# MCASP0_CFG register map
Vendor: Texas Instruments
Registers are 32-bit, read-write, reset 0x0 unless marked. A register's access mark holds for its fields unless they carry their own. Offsets are as the file gives them; [hi:lo] are bit positions.

## MCASP0_CFG (part 3 of 3)
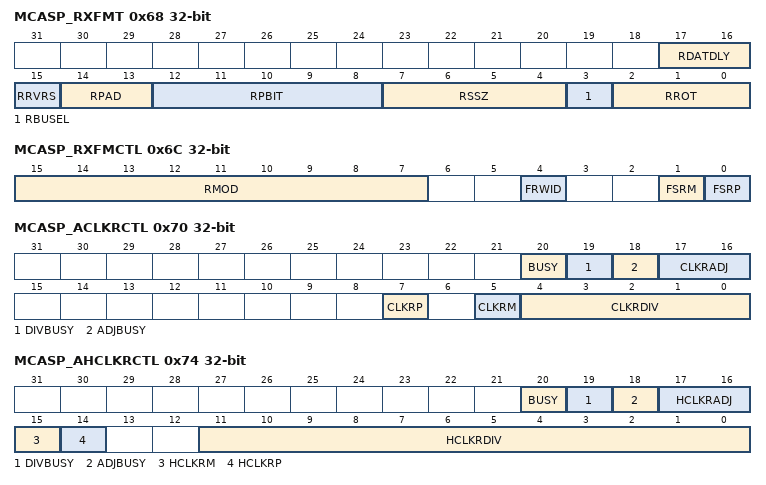
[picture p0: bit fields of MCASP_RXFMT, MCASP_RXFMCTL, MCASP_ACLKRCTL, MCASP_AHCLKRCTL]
0x68 MCASP_RXFMT
  [17:16] RDATDLY — Receive bit delay.0h = 0-bit delay. The first receive data bit, AXRn, occurs in same ACLKR cycle as the receive frame sync (AFSR). 1h = 1-bit delay. The first receive data bit, AXRn, occurs one ACLKR cycle after the receive frame sync (AFSR). 2h = 2-bit delay. The first receive data bit, AXRn, occurs two ACLKR cycles after the receive frame sync (AFSR). 3h = Reserved.
  [15] RRVRS — Receive serial bitstream order.0h = Bitstream is LSB first. No bit reversal is performed in receive format bit reverse unit. 1h = Bitstream is MSB first. Bit reversal is performed in receive format bit reverse unit.
  [14:13] RPAD — Pad value for extra bits in slot not belonging to the word. This field only applies to bits when MCASP_RMASK[n] = 0. 0h = Pad extra bits with 0. 1h = Pad extra bits with 1. 2h = Pad extra bits with one of the bits from the word as specified by RPBIT bits. 3h = Reserved.
  [12:8] RPBIT — RPBIT value determines which bit [as read by the CPU or DMA from RBUF[n]] is used to pad the extra bits. This field only applies when RPAD = 2h. 0h = Pad with bit 0 value. 1h = Pad with bit 1 to bit 31 value from 1h to 1Fh.
  [7:4] RSSZ — Receive slot size.0h = Reseved. 1h = Reserved. 2h = Reserved. 3h = Slot size is 8 bits. 4h = Reserved 5h = Slot size is 12 bits. 6h = Reserved 7h = Slot size is 16 bits. 8h = Reserved 9h = Slot size is 20 bits. Ah = Reserved Bh = Slot size is 24 bits Ch = Reserved Dh = Slot size is 28 bits. Eh = Reserved Fh = Slot size is 32 bits.
  [3] RBUSEL — Selects whether reads from serializer buffer XRBUF[n] originate from the configuration bus [CFG] or the data [DAT] port.0h = Reads from XRBUF[n] originate on data port. Reads from XRBUF[n] on configuration bus are ignored. 1h = Reads from XRBUF[n] originate on configuration bus. Reads from XRBUF[n] on data port are ignored.
  [2:0] RROT — Right-rotation value for receive rotate right format unit.0h = Rotate right by 0 (no rotation). 1h = Rotate right by 4 bit positions. 2h = Rotate right by 8 bit positions. 3h = Rotate right by 12 bit positions. 4h = Rotate right by 16 bit positions. 5h = Rotate right by 20 bit positions. 6h = Rotate right by 24 bit positions. 7h = Rotate right by 28 bit positions.
0x6C MCASP_RXFMCTL
  [15:7] RMOD — Receive frame sync mode select bits. 1FFh = Reserved from 181h to 1FFh. 0h = Burst mode. 1h = Reserved. 2h = 2-slot TDM (I2S mode) to 32-slot TDM from 2h to 20h. 21h = Reserved from 21h to 17Fh. 180h = 384-slot TDM (external DIR IC inputting 384-slot DIR frames to McASP over I2S interface). 181h = Reserved from 181h to 1FFh.
  [4] FRWID — Receive frame sync width select bit indicates the width of the receive frame sync [AFSR] during its active period.0h = Single bit. 1h = Single word.
  [1] FSRM — Receive frame sync generation select bit.0h = Externally-generated receive frame sync. 1h = Internally-generated receive frame sync.
  [0] FSRP — Receive frame sync polarity select bit.0h = A rising edge on receive frame sync (AFSR) indicates the beginning of a frame. 1h = A falling edge on receive frame sync (AFSR) indicates the beginning of a frame.
0x70 MCASP_ACLKRCTL access per field
  [20] BUSY rw — Тhe OR of bits 18 and 19, indicating that some clk change is in progress when high.
  [19] DIVBUSY rw — Divider change in progress (same behavior as bit 18)
  [18] ADJBUSY rw — One-shot adj in progress (a BUSY bit that is set when an adj is in progress, cleared when the adjustment has taken effect)
  [17:16] CLKRADJ wo — CLKRDIV one-shot adjustment contro.l If CLKRDIV is set such that there are “m” input clocks per one output clock, then for one output cycle: 0h = (m+0) input clocks per output clock, no adjustment 1h = (m-1) input clocks per output clock 2h = (m+1) input clocks per output clock 3h = (m+0) input clocks per output clock, no adjustment
  [7] CLKRP rw — Bitstream clock polarity for receive section: 0h = Falling Edge. Receiver captures sample data on the falling edge of the serial clock, so the EXTERNAL transmitter driving this receiver must shift data out on the rising edge of the serial clock. 1h = Rising Edge. Receiver captures sample data on the rising edge of the serial clock, so the EXTERNAL transmitter driving this receiver must shift data out on the falling edge of the serial clock.
  [5] CLKRM rw — Receive clock source: 0h = External Transmit Clock From ACLKR pin 1h = Internal (output of divider), output clock on ACLKR pin.
  [4:0] CLKRDIV rw — Receive clock divide ratio from high frequency transmit clock: 00000b = /1 00001b = /2 . . . 11111b = /32 All values between /1 and /32 are supported.
0x74 MCASP_AHCLKRCTL access per field
  [20] BUSY rw — The OR of bits 18 and 19, indicating that some clk change is in progress when high.
  [19] DIVBUSY rw — Divider change in progress (same behavior as bit 18)
  [18] ADJBUSY rw — One-shot adj in progress (a BUSY bit that is set when an adj is in progress, cleared when the adjustment has taken effect).
  [17:16] HCLKRADJ wo — HCLKRDIV one-shot adjustment control If HCLKRDIV is set such that there are “m” input clocks per one output clock, then for one output cycle: 0h = (m+0) input clocks per output clock 1h = (m-1) input clocks per output clock 2h = (m+1) input clocks per output clock 3h = (m+0) input clocks per output clock
  [15] HCLKRM rw — High frequency receive clock source: 0h = External Clock on AHCLKR pin passes through divider (typically set to /1). 1h = Internal, CPU Clock passed through divider. Divider output on AHCLKR pin.
  [14] HCLKRP rw — high frequency clock polarity: 0h = AHCLKR not inverted before divider. Rising Edge of AHCLKR causes edges on ACLKR when internally generated. 1h = AHCLKR inverted before divider. Falling Edge of AHCLK causes edges on ACLKR when internally generated. For the /1 clock divider case, AHCLKR is just passed through to ACLKR. For odd dividers, both edges of AHCLKR cause ACLKR to toggle but this polarity bit defines which is first edge of AHCLKR to affect ACLKR.
  [11:0] HCLKRDIV rw — Receive clock divide ratio from CPU master clock or external high frequency clock: 0000 0000 0000b = /1 0000 0000 0001b = /2 . . . 1111 1111 1111b = /4096 All values between /1, and /4096 are supported.
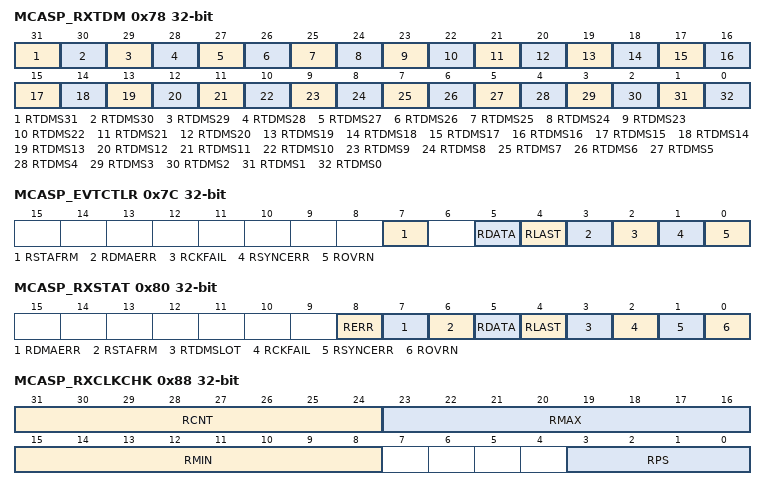
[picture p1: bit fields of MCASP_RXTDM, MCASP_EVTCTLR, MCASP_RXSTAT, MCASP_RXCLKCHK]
0x78 MCASP_RXTDM
  [31] RTDMS31 — Receiver mode during TDM time slot 31.0h = Receive TDM time slot 31 is inactive. The receive serializer does not shift in data during this slot. 1h = Receive TDM time slot 31 is active. The receive serializer shifts in data during this slot.
  [30] RTDMS30 — Receiver mode during TDM time slot 30.0h = Receive TDM time slot 30 is inactive. The receive serializer does not shift in data during this slot. 1h = Receive TDM time slot 30 is active. The receive serializer shifts in data during this slot.
  [29] RTDMS29 — Receiver mode during TDM time slot 29.0h = Receive TDM time slot 29 is inactive. The receive serializer does not shift in data during this slot. 1h = Receive TDM time slot 29 is active. The receive serializer shifts in data during this slot.
  [28] RTDMS28 — Receiver mode during TDM time slot 28.0h = Receive TDM time slot 28 is inactive. The receive serializer does not shift in data during this slot. 1h = Receive TDM time slot 28 is active. The receive serializer shifts in data during this slot.
  [27] RTDMS27 — Receiver mode during TDM time slot 27.0h = Receive TDM time slot 27 is inactive. The receive serializer does not shift in data during this slot. 1h = Receive TDM time slot 27 is active. The receive serializer shifts in data during this slot.
  [26] RTDMS26 — Receiver mode during TDM time slot 26.0h = Receive TDM time slot 26 is inactive. The receive serializer does not shift in data during this slot. 1h = Receive TDM time slot 26 is active. The receive serializer shifts in data during this slot.
  [25] RTDMS25 — Receiver mode during TDM time slot 25.0h = Receive TDM time slot 25 is inactive. The receive serializer does not shift in data during this slot. 1h = Receive TDM time slot 25 is active. The receive serializer shifts in data during this slot.
  [24] RTDMS24 — Receiver mode during TDM time slot 24.0h = Receive TDM time slot 24 is inactive. The receive serializer does not shift in data during this slot. 1h = Receive TDM time slot 24 is active. The receive serializer shifts in data during this slot.
  [23] RTDMS23 — Receiver mode during TDM time slot 23.0h = Receive TDM time slot 23 is inactive. The receive serializer does not shift in data during this slot. 1h = Receive TDM time slot 23 is active. The receive serializer shifts in data during this slot.
  [22] RTDMS22 — Receiver mode during TDM time slot 22.0h = Receive TDM time slot 22 is inactive. The receive serializer does not shift in data during this slot. 1h = Receive TDM time slot 22 is active. The receive serializer shifts in data during this slot.
  [21] RTDMS21 — Receiver mode during TDM time slot 21.0h = Receive TDM time slot 21 is inactive. The receive serializer does not shift in data during this slot. 1h = Receive TDM time slot 21 is active. The receive serializer shifts in data during this slot.
  [20] RTDMS20 — Receiver mode during TDM time slot 20.0h = Receive TDM time slot 20 is inactive. The receive serializer does not shift in data during this slot. 1h = Receive TDM time slot 20 is active. The receive serializer shifts in data during this slot.
  [19] RTDMS19 — Receiver mode during TDM time slot 19.0h = Receive TDM time slot 19 is inactive. The receive serializer does not shift in data during this slot. 1h = Receive TDM time slot 19 is active. The receive serializer shifts in data during this slot.
  [18] RTDMS18 — Receiver mode during TDM time slot 18.0h = Receive TDM time slot 18 is inactive. The receive serializer does not shift in data during this slot. 1h = Receive TDM time slot 18 is active. The receive serializer shifts in data during this slot.
  [17] RTDMS17 — Receiver mode during TDM time slot 17.0h = Receive TDM time slot 17 is inactive. The receive serializer does not shift in data during this slot. 1h = Receive TDM time slot 17 is active. The receive serializer shifts in data during this slot.
  [16] RTDMS16 — Receiver mode during TDM time slot 16.0h = Receive TDM time slot 16 is inactive. The receive serializer does not shift in data during this slot. 1h = Receive TDM time slot 16 is active. The receive serializer shifts in data during this slot.
  [15] RTDMS15 — Receiver mode during TDM time slot 15.0h = Receive TDM time slot 15 is inactive. The receive serializer does not shift in data during this slot. 1h = Receive TDM time slot 15 is active. The receive serializer shifts in data during this slot.
  [14] RTDMS14 — Receiver mode during TDM time slot 14.0h = Receive TDM time slot 14 is inactive. The receive serializer does not shift in data during this slot. 1h = Receive TDM time slot 14 is active. The receive serializer shifts in data during this slot.
  [13] RTDMS13 — Receiver mode during TDM time slot 13.0h = Receive TDM time slot 13 is inactive. The receive serializer does not shift in data during this slot. 1h = Receive TDM time slot 13 is active. The receive serializer shifts in data during this slot.
  [12] RTDMS12 — Receiver mode during TDM time slot 12.0h = Receive TDM time slot 12 is inactive. The receive serializer does not shift in data during this slot. 1h = Receive TDM time slot 12 is active. The receive serializer shifts in data during this slot.
  [11] RTDMS11 — Receiver mode during TDM time slot 11.0h = Receive TDM time slot 11 is inactive. The receive serializer does not shift in data during this slot. 1h = Receive TDM time slot 11 is active. The receive serializer shifts in data during this slot.
  [10] RTDMS10 — Receiver mode during TDM time slot 10.0h = Receive TDM time slot 10 is inactive. The receive serializer does not shift in data during this slot. 1h = Receive TDM time slot 10 is active. The receive serializer shifts in data during this slot.
  [9] RTDMS9 — Receiver mode during TDM time slot 9.0h = Receive TDM time slot 9 is inactive. The receive serializer does not shift in data during this slot. 1h = Receive TDM time slot 9 is active. The receive serializer shifts in data during this slot.
  [8] RTDMS8 — Receiver mode during TDM time slot 8.0h = Receive TDM time slot 8 is inactive. The receive serializer does not shift in data during this slot. 1h = Receive TDM time slot 8 is active. The receive serializer shifts in data during this slot.
  [7] RTDMS7 — Receiver mode during TDM time slot 7.0h = Receive TDM time slot 7 is inactive. The receive serializer does not shift in data during this slot. 1h = Receive TDM time slot 7 is active. The receive serializer shifts in data during this slot.
  [6] RTDMS6 — Receiver mode during TDM time slot 6.0h = Receive TDM time slot 6 is inactive. The receive serializer does not shift in data during this slot. 1h = Receive TDM time slot 6 is active. The receive serializer shifts in data during this slot.
  [5] RTDMS5 — Receiver mode during TDM time slot 5.0h = Receive TDM time slot 5 is inactive. The receive serializer does not shift in data during this slot. 1h = Receive TDM time slot 5 is active. The receive serializer shifts in data during this slot.
  [4] RTDMS4 — Receiver mode during TDM time slot 4.0h = Receive TDM time slot 4 is inactive. The receive serializer does not shift in data during this slot. 1h = Receive TDM time slot 4 is active. The receive serializer shifts in data during this slot.
  [3] RTDMS3 — Receiver mode during TDM time slot 3.0h = Receive TDM time slot 3 is inactive. The receive serializer does not shift in data during this slot. 1h = Receive TDM time slot 3 is active. The receive serializer shifts in data during this slot.
  [2] RTDMS2 — Receiver mode during TDM time slot 2.0h = Receive TDM time slot 2 is inactive. The receive serializer does not shift in data during this slot. 1h = Receive TDM time slot 2 is active. The receive serializer shifts in data during this slot.
  [1] RTDMS1 — Receiver mode during TDM time slot 1.0h = Receive TDM time slot 1 is inactive. The receive serializer does not shift in data during this slot. 1h = Receive TDM time slot 1 is active. The receive serializer shifts in data during this slot.
  [0] RTDMS0 — Receiver mode during TDM time slot 0.0h = Receive TDM time slot 0 is inactive. The receive serializer does not shift in data during this slot. 1h = Receive TDM time slot 0 is active. The receive serializer shifts in data during this slot.
0x7C MCASP_EVTCTLR
  [7] RSTAFRM — Receive start of frame interrupt enable bit.0h = Interrupt is disabled. A receive start of frame interrupt does not generate a MCASP receive interrupt (RINT). 1h = Interrupt is enabled. A receive start of frame interrupt generates a MCASP receive interrupt (RINT).
  [5] RDATA — Receive data ready interrupt enable bit.0h = Interrupt is disabled. A receive data ready interrupt does not generate a MCASP receive interrupt (RINT). 1h = Interrupt is enabled. A receive data ready interrupt generates a MCASP receive interrupt (RINT).
  [4] RLAST — Receive last slot interrupt enable bit.0h = Interrupt is disabled. A receive last slot interrupt does not generate a MCASP receive interrupt (RINT). 1h = Interrupt is enabled. A receive last slot interrupt generates a MCASP receive interrupt (RINT).
  [3] RDMAERR — Receive DMA error interrupt enable bit.0h = Interrupt is disabled. A receive DMA error interrupt does not generate a MCASP receive interrupt (RINT). 1h = Interrupt is enabled. A receive DMA error interrupt generates a MCASP receive interrupt (RINT).
  [2] RCKFAIL — Receive clock failure interrupt enable bit.0h = Interrupt is disabled. A receive clock failure interrupt does not generate a MCASP receive interrupt (RINT). 1h = Interrupt is enabled. A receive clock failure interrupt generates a MCASP receive interrupt (RINT).
  [1] RSYNCERR — Unexpected receive frame sync interrupt enable bit.0h = Interrupt is disabled. An unexpected receive frame sync interrupt does not generate a MCASP receive interrupt (RINT). 1h = Interrupt is enabled. An unexpected receive frame sync interrupt generates a MCASP receive interrupt (RINT).
  [0] ROVRN — Receiver overrun interrupt enable bit.0h = Interrupt is disabled. A receiver overrun interrupt does not generate a MCASP receive interrupt (RINT). 1h = Interrupt is enabled. A receiver overrun interrupt generates a MCASP receive interrupt (RINT).
0x80 MCASP_RXSTAT
  [8] RERR — RERR bit always returns a logic-OR of: ROVRN OR RSYNCERR OR RCKFAIL OR RDMAERR. Allows a single bit to be checked to determine if a receiver error interrupt has occurred. 0h = No errors have occurred. 1h = An error has occurred.
  [7] RDMAERR — Receive DMA error flag. RDMAERR is set when the CPU or DMA reads more serializers through the data port in a given time slot than were programmed as receivers. Causes a receive interrupt [RINT], if this bit is set and RDMAERR in MCASP_RINTCTL is set. This bit is cleared by writing a 1 to this bit. Writing a 0 to this bit has no effect. 0h = Receive DMA error did not occur. 1h = Receive DMA error did occur.
  [6] RSTAFRM — Receive start of frame flag. Causes a receive interrupt [RINT], if this bit is set and RSTAFRM in MCASP_RINTCTL is set. This bit is cleared by writing a 1 to this bit. Writing a 0 to this bit has no effect. 0h = No new receive frame sync (AFSR) is detected. 1h = A new receive frame sync (AFSR) is detected.
  [5] RDATA — Receive data ready flag. Causes a receive interrupt [RINT], if this bit is set and RDATA in MCASP_RINTCTL is set. This bit is cleared by writing a 1 to this bit. Writing a 0 to this bit has no effect. 0h = No new data in RBUF. 1h = Data is transferred from XRSR to RBUF and ready to be serviced by the CPU or DMA. When RDATA is set, it always causes a DMA event (AREVT).
  [4] RLAST — Receive last slot flag. RLAST is set along with RDATA, if the current slot is the last slot in a frame. Causes a receive interrupt [RINT], if this bit is set and RLAST in MCASP_RINTCTL is set. This bit is cleared by writing a 1 to this bit. Writing a 0 to this bit has no effect. 0h = Current slot is not the last slot in a frame. 1h = Current slot is the last slot in a frame. RDATA is also set.
  [3] RTDMSLOT — Returns the LSB of MCASP_RSLOT. Allows a single read of MCASP_RSTAT to determine whether the current TDM time slot is even or odd. 0h = Current TDM time slot is odd. 1h = Current TDM time slot is even.
  [2] RCKFAIL — Receive clock failure flag. RCKFAIL is set when the receive clock failure detection circuit reports an error. Causes a receive interrupt [RINT], if this bit is set and RCKFAIL in MCASP_RINTCTL is set. This bit is cleared by writing a 1 to this bit. Writing a 0 to this bit has no effect. 0h = Receive clock failure did not occur. 1h = Receive clock failure did occur.
  [1] RSYNCERR — Unexpected receive frame sync flag. RSYNCERR is set when a new receive frame sync [AFSR] occurs before it is expected. Causes a receive interrupt [RINT], if this bit is set and RSYNCERR in MCASP_RINTCTL is set. This bit is cleared by writing a 1 to this bit. Writing a 0 to this bit has no effect. 0h = Unexpected receive frame sync did not occur. 1h = Unexpected receive frame sync did occur.
  [0] ROVRN — Receiver overrun flag. ROVRN is set when the receive serializer is instructed to transfer data from XRSR to RBUF, but the former data in RBUF has not yet been read by the CPU or DMA. Causes a receive interrupt [RINT], if this bit is set and ROVRN in MCASP_RINTCTL is set. This bit is cleared by writing a 1 to this bit. Writing a 0 to this bit has no effect. 0h = Receiver overrun did not occur. 1h = Receiver overrun did occur.
0x84 MCASP_RXTDMSLOT ro
  [9:0] RSLOTCNT — 0-17Fh = Current receive time slot count. Legal values: 0 to 383 [17Fh]. TDM function is not supported for &gt; 32 time slots. However, TDM time slot counter may count to 383 when used to receive a DIR block [transferred over TDM format].
0x88 MCASP_RXCLKCHK access per field
  [31:24] RCNT ro — Receive clock count value [from previous measurement]. The clock circuit continually counts the number of system clocks for every 32 receive high-frequency master clock [AHCLKR] signals, and stores the count in RCNT until the next measurement is taken.
  [23:16] RMAX rw — Receive clock maximum boundary. This 8 bit unsigned value sets the maximum allowed boundary for the clock check counter after 32 receive high-frequency master clock [AHCLKR] signals have been received. If the current counter value is greater than RMAX after counting 32 AHCLKR signals, RCKFAIL in MCASP_RSTAT is set. The comparison is performed using unsigned arithmetic.
  [15:8] RMIN rw — Receive clock minimum boundary. This 8 bit unsigned value sets the minimum allowed boundary for the clock check counter after 32 receive high-frequency master clock [AHCLKR] signals have been received. If RCNT is less than RMIN after counting 32 AHCLKR signals, RCKFAIL in MCASP_RSTAT is set. The comparison is performed using unsigned arithmetic.
  [3:0] RPS rw — Receive clock check prescaler value.0h = MCASP system clock divided by 1. 1h = MCASP system clock divided by 2. 2h = MCASP system clock divided by 4. 3h = MCASP system clock divided by 8. 4h = MCASP system clock divided by 16. 5h = MCASP system clock divided by 32. 6h = MCASP system clock divided by 64. 7h = MCASP system clock divided by 128. 8h = MCASP system clock divided by 256. 9h = Reserved from 9h to Fh.
0x8C MCASP_REVTCTL
  [0] RDATDMA — Receive data DMA request enable bit. If writing to this bit, always write the default value of 0. 0h = Receive data DMA request is enabled. 1h = Reserved
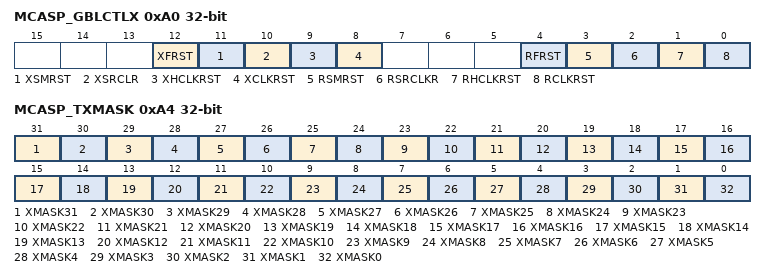
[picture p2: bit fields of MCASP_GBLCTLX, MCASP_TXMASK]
0xA0 MCASP_GBLCTLX access per field
  [12] XFRST rw — Transmit frame sync generator reset enable bit. A write to this bit affects the XFRST bit of MCASP_GBLCTL. 0h = Transmit frame sync generator is reset. 1h = Transmit frame sync generator is active.
  [11] XSMRST rw — Transmit state machine reset enable bit. A write to this bit affects the XSMRST bit of MCASP_GBLCTL. 0h = Transmit state machine is held in reset. 1h = Transmit state machine is released from reset.
  [10] XSRCLR rw — Transmit serializer clear enable bit. A write to this bit affects the XSRCLR bit of MCASP_GBLCTL. 0h = Transmit serializers are cleared. 1h = Transmit serializers are active.
  [9] XHCLKRST rw — Transmit high-frequency clock divider reset enable bit. A write to this bit affects the XHCLKRST bit of MCASP_GBLCTL. 0h = Transmit high-frequency clock divider is held in reset. 1h = Transmit high-frequency clock divider is running.
  [8] XCLKRST rw — Transmit clock divider reset enable bit. A write to this bit affects the XCLKRST bit of MCASP_GBLCTL. 0h = Transmit clock divider is held in reset. 1h = Transmit clock divider is running.
  [4] RFRST ro — Receive frame sync generator reset enable bit. A read of this bit returns the RFRST bit value of MCASP_GBLCTL. Writes have no effect.
  [3] RSMRST ro — Receive state machine reset enable bit. A read of this bit returns the RSMRST bit value of MCASP_GBLCTL. Writes have no effect.
  [2] RSRCLKR ro — Receive serializer clear enable bit. A read of this bit returns the RSRSCLR bit value of MCASP_GBLCTL. Writes have no effect.
  [1] RHCLKRST ro — Receive high-frequency clock divider reset enable bit. A read of this bit returns the RHCLKRST bit value of MCASP_GBLCTL. Writes have no effect.
  [0] RCLKRST ro — Receive clock divider reset enable bit. A read of this bit returns the RCLKRST bit value of MCASP_GBLCTL. Writes have no effect.
0xA4 MCASP_TXMASK
  [31] XMASK31 — Transmit data mask 31 enable bit.0h = Corresponding bit of transmit data (before passing through reverse and rotate units) is masked out and then padded with the selected bit pad value (XPAD and XPBIT bits in MCASP_XFMT), which is transmitted out the McASP in place of the original bit. 1h = Corresponding bit of transmit data (before passing through reverse and rotate units) is transmitted out the McASP.
  [30] XMASK30 — Transmit data mask 30 enable bit.0h = Corresponding bit of transmit data (before passing through reverse and rotate units) is masked out and then padded with the selected bit pad value (XPAD and XPBIT bits in MCASP_XFMT), which is transmitted out the McASP in place of the original bit. 1h = Corresponding bit of transmit data (before passing through reverse and rotate units) is transmitted out the McASP.
  [29] XMASK29 — Transmit data mask 29 enable bit.0h = Corresponding bit of transmit data (before passing through reverse and rotate units) is masked out and then padded with the selected bit pad value (XPAD and XPBIT bits in MCASP_XFMT), which is transmitted out the McASP in place of the original bit. 1h = Corresponding bit of transmit data (before passing through reverse and rotate units) is transmitted out the McASP.
  [28] XMASK28 — Transmit data mask 28 enable bit.0h = Corresponding bit of transmit data (before passing through reverse and rotate units) is masked out and then padded with the selected bit pad value (XPAD and XPBIT bits in MCASP_XFMT), which is transmitted out the McASP in place of the original bit. 1h = Corresponding bit of transmit data (before passing through reverse and rotate units) is transmitted out the McASP.
  [27] XMASK27 — Transmit data mask 27 enable bit.0h = Corresponding bit of transmit data (before passing through reverse and rotate units) is masked out and then padded with the selected bit pad value (XPAD and XPBIT bits in MCASP_XFMT), which is transmitted out the McASP in place of the original bit. 1h = Corresponding bit of transmit data (before passing through reverse and rotate units) is transmitted out the McASP.
  [26] XMASK26 — Transmit data mask 26 enable bit.0h = Corresponding bit of transmit data (before passing through reverse and rotate units) is masked out and then padded with the selected bit pad value (XPAD and XPBIT bits in MCASP_XFMT), which is transmitted out the McASP in place of the original bit. 1h = Corresponding bit of transmit data (before passing through reverse and rotate units) is transmitted out the McASP.
  [25] XMASK25 — Transmit data mask 25 enable bit.0h = Corresponding bit of transmit data (before passing through reverse and rotate units) is masked out and then padded with the selected bit pad value (XPAD and XPBIT bits in MCASP_XFMT), which is transmitted out the McASP in place of the original bit. 1h = Corresponding bit of transmit data (before passing through reverse and rotate units) is transmitted out the McASP.
  [24] XMASK24 — Transmit data mask 24 enable bit.0h = Corresponding bit of transmit data (before passing through reverse and rotate units) is masked out and then padded with the selected bit pad value (XPAD and XPBIT bits in MCASP_XFMT), which is transmitted out the McASP in place of the original bit. 1h = Corresponding bit of transmit data (before passing through reverse and rotate units) is transmitted out the McASP.
  [23] XMASK23 — Transmit data mask 23 enable bit.0h = Corresponding bit of transmit data (before passing through reverse and rotate units) is masked out and then padded with the selected bit pad value (XPAD and XPBIT bits in MCASP_XFMT), which is transmitted out the McASP in place of the original bit. 1h = Corresponding bit of transmit data (before passing through reverse and rotate units) is transmitted out the McASP.
  [22] XMASK22 — Transmit data mask 22 enable bit.0h = Corresponding bit of transmit data (before passing through reverse and rotate units) is masked out and then padded with the selected bit pad value (XPAD and XPBIT bits in MCASP_XFMT), which is transmitted out the McASP in place of the original bit. 1h = Corresponding bit of transmit data (before passing through reverse and rotate units) is transmitted out the McASP.
  [21] XMASK21 — Transmit data mask 21 enable bit.0h = Corresponding bit of transmit data (before passing through reverse and rotate units) is masked out and then padded with the selected bit pad value (XPAD and XPBIT bits in MCASP_XFMT), which is transmitted out the McASP in place of the original bit. 1h = Corresponding bit of transmit data (before passing through reverse and rotate units) is transmitted out the McASP.
  [20] XMASK20 — Transmit data mask 20 enable bit.0h = Corresponding bit of transmit data (before passing through reverse and rotate units) is masked out and then padded with the selected bit pad value (XPAD and XPBIT bits in MCASP_XFMT), which is transmitted out the McASP in place of the original bit. 1h = Corresponding bit of transmit data (before passing through reverse and rotate units) is transmitted out the McASP.
  [19] XMASK19 — Transmit data mask 19 enable bit.0h = Corresponding bit of transmit data (before passing through reverse and rotate units) is masked out and then padded with the selected bit pad value (XPAD and XPBIT bits in MCASP_XFMT), which is transmitted out the McASP in place of the original bit. 1h = Corresponding bit of transmit data (before passing through reverse and rotate units) is transmitted out the McASP.
  [18] XMASK18 — Transmit data mask 18 enable bit.0h = Corresponding bit of transmit data (before passing through reverse and rotate units) is masked out and then padded with the selected bit pad value (XPAD and XPBIT bits in MCASP_XFMT), which is transmitted out the McASP in place of the original bit. 1h = Corresponding bit of transmit data (before passing through reverse and rotate units) is transmitted out the McASP.
  [17] XMASK17 — Transmit data mask 17 enable bit.0h = Corresponding bit of transmit data (before passing through reverse and rotate units) is masked out and then padded with the selected bit pad value (XPAD and XPBIT bits in MCASP_XFMT), which is transmitted out the McASP in place of the original bit. 1h = Corresponding bit of transmit data (before passing through reverse and rotate units) is transmitted out the McASP.
  [16] XMASK16 — Transmit data mask 16 enable bit.0h = Corresponding bit of transmit data (before passing through reverse and rotate units) is masked out and then padded with the selected bit pad value (XPAD and XPBIT bits in MCASP_XFMT), which is transmitted out the McASP in place of the original bit. 1h = Corresponding bit of transmit data (before passing through reverse and rotate units) is transmitted out the McASP.
  [15] XMASK15 — Transmit data mask 15 enable bit.0h = Corresponding bit of transmit data (before passing through reverse and rotate units) is masked out and then padded with the selected bit pad value (XPAD and XPBIT bits in MCASP_XFMT), which is transmitted out the McASP in place of the original bit. 1h = Corresponding bit of transmit data (before passing through reverse and rotate units) is transmitted out the McASP.
  [14] XMASK14 — Transmit data mask 14 enable bit.0h = Corresponding bit of transmit data (before passing through reverse and rotate units) is masked out and then padded with the selected bit pad value (XPAD and XPBIT bits in MCASP_XFMT), which is transmitted out the McASP in place of the original bit. 1h = Corresponding bit of transmit data (before passing through reverse and rotate units) is transmitted out the McASP.
  [13] XMASK13 — Transmit data mask 13 enable bit.0h = Corresponding bit of transmit data (before passing through reverse and rotate units) is masked out and then padded with the selected bit pad value (XPAD and XPBIT bits in MCASP_XFMT), which is transmitted out the McASP in place of the original bit. 1h = Corresponding bit of transmit data (before passing through reverse and rotate units) is transmitted out the McASP.
  [12] XMASK12 — Transmit data mask 12 enable bit.0h = Corresponding bit of transmit data (before passing through reverse and rotate units) is masked out and then padded with the selected bit pad value (XPAD and XPBIT bits in MCASP_XFMT), which is transmitted out the McASP in place of the original bit. 1h = Corresponding bit of transmit data (before passing through reverse and rotate units) is transmitted out the McASP.
  [11] XMASK11 — Transmit data mask 11 enable bit.0h = Corresponding bit of transmit data (before passing through reverse and rotate units) is masked out and then padded with the selected bit pad value (XPAD and XPBIT bits in MCASP_XFMT), which is transmitted out the McASP in place of the original bit. 1h = Corresponding bit of transmit data (before passing through reverse and rotate units) is transmitted out the McASP.
  [10] XMASK10 — Transmit data mask 10 enable bit.0h = Corresponding bit of transmit data (before passing through reverse and rotate units) is masked out and then padded with the selected bit pad value (XPAD and XPBIT bits in MCASP_XFMT), which is transmitted out the McASP in place of the original bit. 1h = Corresponding bit of transmit data (before passing through reverse and rotate units) is transmitted out the McASP.
  [9] XMASK9 — Transmit data mask 9 enable bit.0h = Corresponding bit of transmit data (before passing through reverse and rotate units) is masked out and then padded with the selected bit pad value (XPAD and XPBIT bits in MCASP_XFMT), which is transmitted out the McASP in place of the original bit. 1h = Corresponding bit of transmit data (before passing through reverse and rotate units) is transmitted out the McASP.
  [8] XMASK8 — Transmit data mask 8 enable bit.0h = Corresponding bit of transmit data (before passing through reverse and rotate units) is masked out and then padded with the selected bit pad value (XPAD and XPBIT bits in MCASP_XFMT), which is transmitted out the McASP in place of the original bit. 1h = Corresponding bit of transmit data (before passing through reverse and rotate units) is transmitted out the McASP.
  [7] XMASK7 — Transmit data mask 7 enable bit.0h = Corresponding bit of transmit data (before passing through reverse and rotate units) is masked out and then padded with the selected bit pad value (XPAD and XPBIT bits in MCASP_XFMT), which is transmitted out the McASP in place of the original bit. 1h = Corresponding bit of transmit data (before passing through reverse and rotate units) is transmitted out the McASP.
  [6] XMASK6 — Transmit data mask 6 enable bit.0h = Corresponding bit of transmit data (before passing through reverse and rotate units) is masked out and then padded with the selected bit pad value (XPAD and XPBIT bits in MCASP_XFMT), which is transmitted out the McASP in place of the original bit. 1h = Corresponding bit of transmit data (before passing through reverse and rotate units) is transmitted out the McASP.
  [5] XMASK5 — Transmit data mask 5 enable bit.0h = Corresponding bit of transmit data (before passing through reverse and rotate units) is masked out and then padded with the selected bit pad value (XPAD and XPBIT bits in MCASP_XFMT), which is transmitted out the McASP in place of the original bit. 1h = Corresponding bit of transmit data (before passing through reverse and rotate units) is transmitted out the McASP.
  [4] XMASK4 — Transmit data mask 4 enable bit.0h = Corresponding bit of transmit data (before passing through reverse and rotate units) is masked out and then padded with the selected bit pad value (XPAD and XPBIT bits in MCASP_XFMT), which is transmitted out the McASP in place of the original bit. 1h = Corresponding bit of transmit data (before passing through reverse and rotate units) is transmitted out the McASP.
  [3] XMASK3 — Transmit data mask 3 enable bit.0h = Corresponding bit of transmit data (before passing through reverse and rotate units) is masked out and then padded with the selected bit pad value (XPAD and XPBIT bits in MCASP_XFMT), which is transmitted out the McASP in place of the original bit. 1h = Corresponding bit of transmit data (before passing through reverse and rotate units) is transmitted out the McASP.
  [2] XMASK2 — Transmit data mask 2 enable bit.0h = Corresponding bit of transmit data (before passing through reverse and rotate units) is masked out and then padded with the selected bit pad value (XPAD and XPBIT bits in MCASP_XFMT), which is transmitted out the McASP in place of the original bit. 1h = Corresponding bit of transmit data (before passing through reverse and rotate units) is transmitted out the McASP.
  [1] XMASK1 — Transmit data mask 1 enable bit.0h = Corresponding bit of transmit data (before passing through reverse and rotate units) is masked out and then padded with the selected bit pad value (XPAD and XPBIT bits in MCASP_XFMT), which is transmitted out the McASP in place of the original bit. 1h = Corresponding bit of transmit data (before passing through reverse and rotate units) is transmitted out the McASP.
  [0] XMASK0 — Transmit data mask 0 enable bit.0h = Corresponding bit of transmit data (before passing through reverse and rotate units) is masked out and then padded with the selected bit pad value (XPAD and XPBIT bits in MCASP_XFMT), which is transmitted out the McASP in place of the original bit. 1h = Corresponding bit of transmit data (before passing through reverse and rotate units) is transmitted out the McASP.
